# PIC32MK0512GPL064 register map
Vendor: Microchip
Registers are 32-bit, read-write, no defined reset value unless marked. A register's access mark holds for its fields unless they carry their own. Addresses are absolute, and some are shared; only a register's first bit layout is shown; [hi:lo] are bit positions; {n}, {i} and the like mark numbered series.

## CDAC3
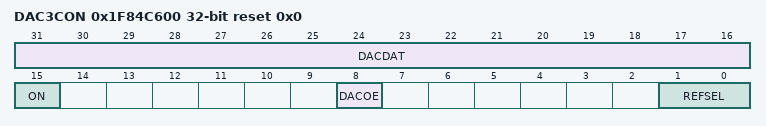
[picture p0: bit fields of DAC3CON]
0x1F84C600 DAC3CON reset 0x0 — CDAC Control Register
  [31:16] DACDAT — Data Input Register Bits for the CDAC
  [15] ON — CDAC Enable
    0=The CDAC is Disabled; 1=The CDAC is Enabled
  [8] DACOE — CDAC Output Enable
    0=Output is Disabled; drive to pin is floating; 1=Output is Enabled; CDAC voltage is connected to the pin
  [1:0] REFSEL — Reference Source Select
    0=No Reference Selected (no current consumed); 1=Positive Reference Voltage = External Vref+ Pin; 2=Positive Reference Voltage = 2 * Internal Bandgap Reference Voltage; 3=Positive Reference Voltage = AVdd

## gpio_ports_upb
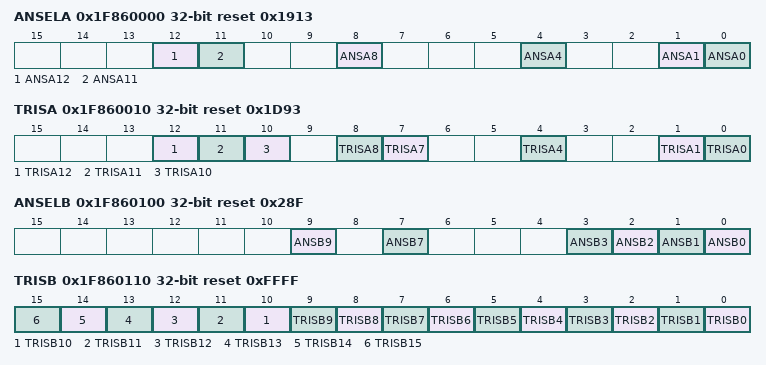
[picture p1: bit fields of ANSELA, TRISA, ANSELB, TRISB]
0x1F860000 ANSELA reset 0x1913
  [12] ANSA12, [11] ANSA11, [8] ANSA8, [4] ANSA4, [1] ANSA1, [0] ANSA0
0x1F860010 TRISA reset 0x1D93
  [12] TRISA12, [11] TRISA11, [10] TRISA10, [8] TRISA8, [7] TRISA7, [4] TRISA4, [1] TRISA1, [0] TRISA0
0x1F860100 ANSELB reset 0x28F
  [9] ANSB9, [7] ANSB7, [n] ANSB{n} (n=0..3)
0x1F860110 TRISB reset 0xFFFF
  [n] TRISB{n} (n=0..15)
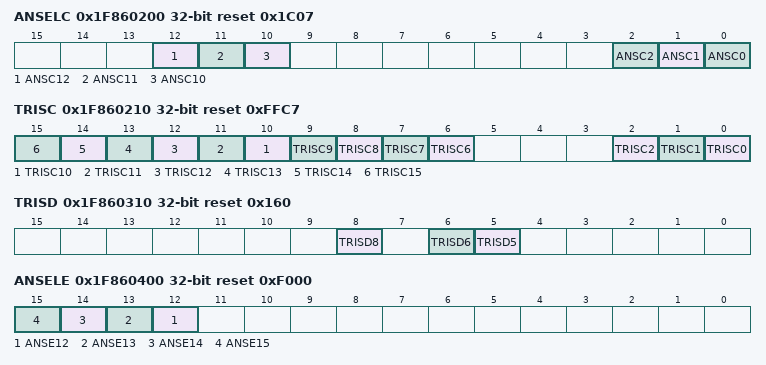
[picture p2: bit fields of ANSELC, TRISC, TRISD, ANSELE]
0x1F860200 ANSELC reset 0x1C07
  [12] ANSC12, [11] ANSC11, [10] ANSC10, [2] ANSC2, [1] ANSC1, [0] ANSC0
0x1F860210 TRISC reset 0xFFC7
  [n] TRISC{n} (n=6..15), [2] TRISC2, [1] TRISC1, [0] TRISC0
0x1F860310 TRISD reset 0x160
  [8] TRISD8, [6] TRISD6, [5] TRISD5
0x1F860400 ANSELE reset 0xF000
  [n] ANSE{n} (n=12..15)
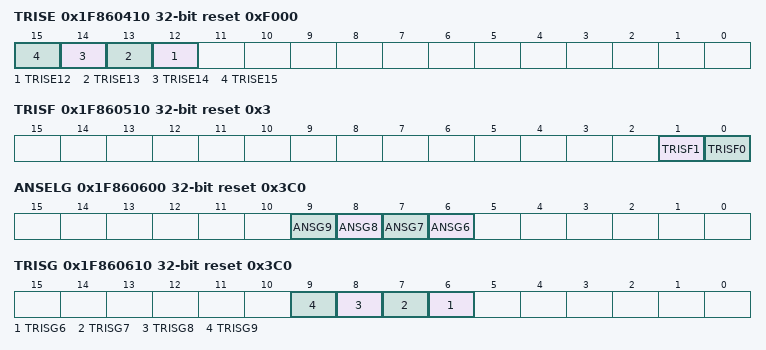
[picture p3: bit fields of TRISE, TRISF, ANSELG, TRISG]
0x1F860410 TRISE reset 0xF000
  [n] TRISE{n} (n=12..15)
0x1F860510 TRISF reset 0x3
  [1] TRISF1, [0] TRISF0
0x1F860600 ANSELG reset 0x3C0
  [n] ANSG{n} (n=6..9)
0x1F860610 TRISG reset 0x3C0
  [n] TRISG{n} (n=6..9)

## PORTA
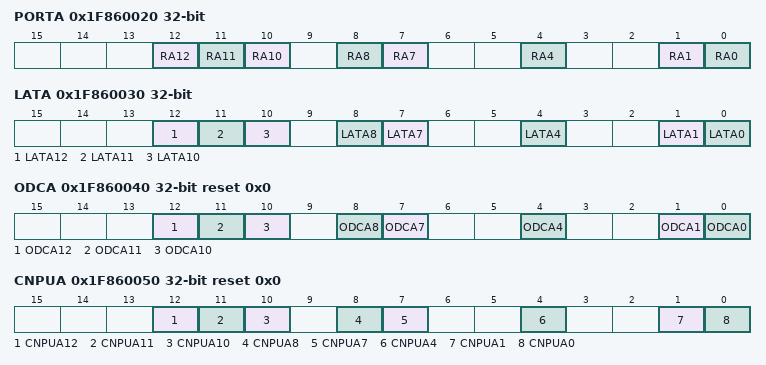
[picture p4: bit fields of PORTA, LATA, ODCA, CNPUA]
0x1F860020 PORTA — (power-on value -------------------xxx-xx--x--xx)
  [12] RA12, [11] RA11, [10] RA10, [8] RA8, [7] RA7, [4] RA4, [1] RA1, [0] RA0
0x1F860030 LATA — (power-on value -------------------xxx-xx--x--xx)
  [12] LATA12, [11] LATA11, [10] LATA10, [8] LATA8, [7] LATA7, [4] LATA4, [1] LATA1, [0] LATA0
0x1F860040 ODCA reset 0x0
  [12] ODCA12, [11] ODCA11, [10] ODCA10, [8] ODCA8, [7] ODCA7, [4] ODCA4, [1] ODCA1, [0] ODCA0
0x1F860050 CNPUA reset 0x0
  [12] CNPUA12, [11] CNPUA11, [10] CNPUA10, [8] CNPUA8, [7] CNPUA7, [4] CNPUA4, [1] CNPUA1, [0] CNPUA0
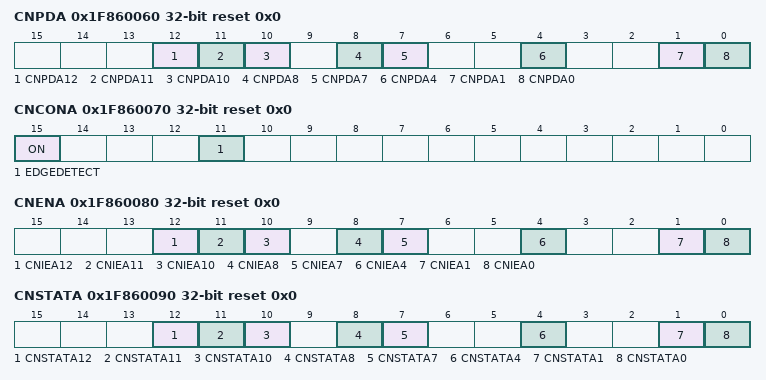
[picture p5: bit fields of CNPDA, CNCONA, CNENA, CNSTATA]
0x1F860060 CNPDA reset 0x0
  [12] CNPDA12, [11] CNPDA11, [10] CNPDA10, [8] CNPDA8, [7] CNPDA7, [4] CNPDA4, [1] CNPDA1, [0] CNPDA0
0x1F860070 CNCONA reset 0x0
  [15] ON, [11] EDGEDETECT
0x1F860080 CNENA reset 0x0
  [12] CNIEA12, [11] CNIEA11, [10] CNIEA10, [8] CNIEA8, [7] CNIEA7, [4] CNIEA4, [1] CNIEA1, [0] CNIEA0
0x1F860090 CNSTATA reset 0x0
  [12] CNSTATA12, [11] CNSTATA11, [10] CNSTATA10, [8] CNSTATA8, [7] CNSTATA7, [4] CNSTATA4, [1] CNSTATA1, [0] CNSTATA0
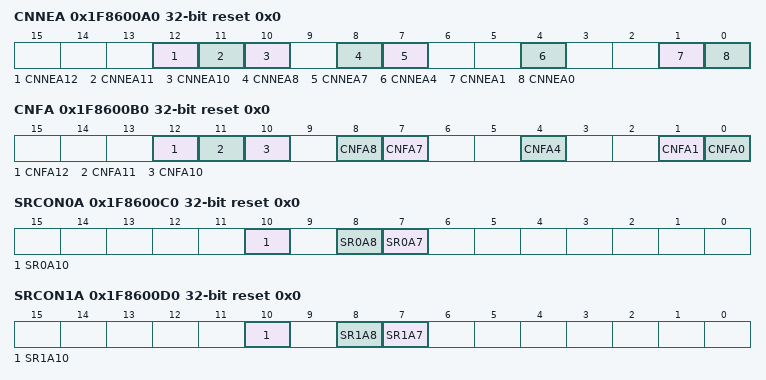
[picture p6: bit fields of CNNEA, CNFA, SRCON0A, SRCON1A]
0x1F8600A0 CNNEA reset 0x0
  [12] CNNEA12, [11] CNNEA11, [10] CNNEA10, [8] CNNEA8, [7] CNNEA7, [4] CNNEA4, [1] CNNEA1, [0] CNNEA0
0x1F8600B0 CNFA reset 0x0
  [12] CNFA12, [11] CNFA11, [10] CNFA10, [8] CNFA8, [7] CNFA7, [4] CNFA4, [1] CNFA1, [0] CNFA0
0x1F8600C0 SRCON0A reset 0x0
  [10] SR0A10, [8] SR0A8, [7] SR0A7
0x1F8600D0 SRCON1A reset 0x0
  [10] SR1A10, [8] SR1A8, [7] SR1A7

## PORTB
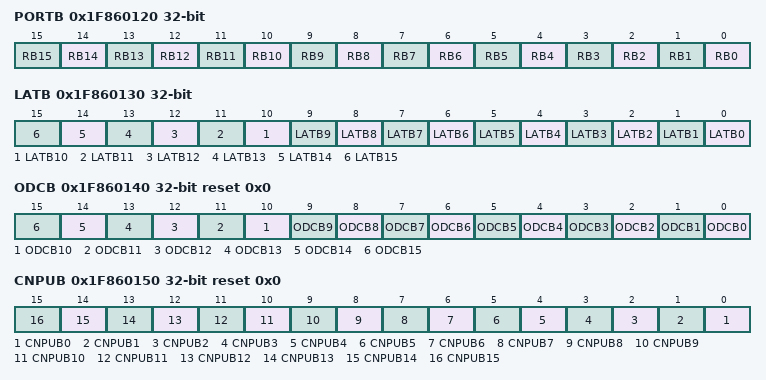
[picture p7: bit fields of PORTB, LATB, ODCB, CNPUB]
0x1F860120 PORTB — (power-on value ----------------xxxxxxxxxxxxxxxx)
  [n] RB{n} (n=0..15)
0x1F860130 LATB — (power-on value ----------------xxxxxxxxxxxxxxxx)
  [n] LATB{n} (n=0..15)
0x1F860140 ODCB reset 0x0
  [n] ODCB{n} (n=0..15)
0x1F860150 CNPUB reset 0x0
  [n] CNPUB{n} (n=0..15)
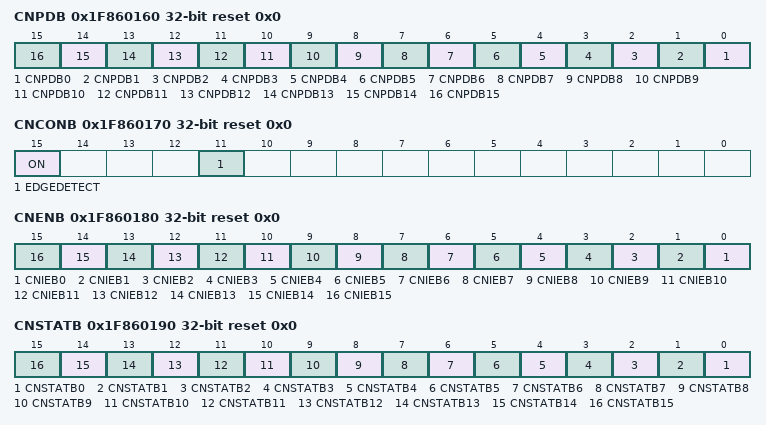
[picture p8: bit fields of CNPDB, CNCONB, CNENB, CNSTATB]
0x1F860160 CNPDB reset 0x0
  [n] CNPDB{n} (n=0..15)
0x1F860170 CNCONB reset 0x0
  [15] ON, [11] EDGEDETECT
0x1F860180 CNENB reset 0x0
  [n] CNIEB{n} (n=0..15)
0x1F860190 CNSTATB reset 0x0
  [n] CNSTATB{n} (n=0..15)
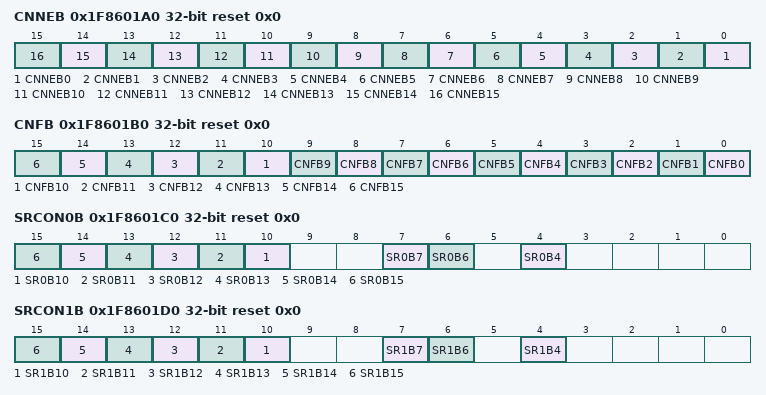
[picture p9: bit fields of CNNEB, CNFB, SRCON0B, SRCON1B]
0x1F8601A0 CNNEB reset 0x0
  [n] CNNEB{n} (n=0..15)
0x1F8601B0 CNFB reset 0x0
  [n] CNFB{n} (n=0..15)
0x1F8601C0 SRCON0B reset 0x0
  [n] SR0B{n} (n=10..15), [7] SR0B7, [6] SR0B6, [4] SR0B4
0x1F8601D0 SRCON1B reset 0x0
  [n] SR1B{n} (n=10..15), [7] SR1B7, [6] SR1B6, [4] SR1B4
